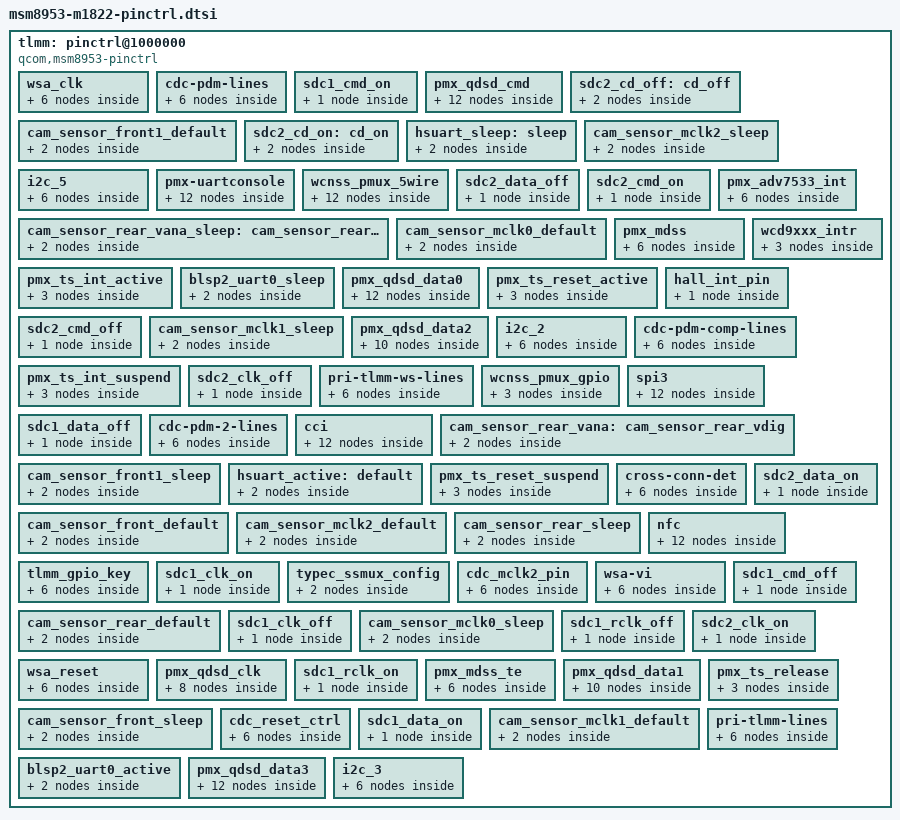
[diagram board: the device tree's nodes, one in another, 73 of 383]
		tlmm: pinctrl@1000000 {
			interrupts-extended = <0x01 0x00 0xd0 0x00>;
			compatible = "qcom,msm8953-pinctrl";
			gpio-controller;
			#interrupt-cells = <0x02>;
			interrupt-parent = <0x10>;
			interrupts = <0x00 0xd0 0x00>;
			phandle = <0xc3>;
			reg = <0x1000000 0x300000>;
			#gpio-cells = <0x02>;
			linux,phandle = <0xc3>;
			interrupt-controller;

			wsa_clk {

				wsa_clk_on: wsa_clk_on {
					phandle = <0x192>;
					linux,phandle = <0x192>;

					mux {
						pins = "gpio25";
						function = "pri_mi2s_mclk_a";
					};

					config {
						pins = "gpio25";
						drive-strength = <0x08>;
						output-high;
					};
				};

				wsa_clk_off: wsa_clk_off {
					phandle = <0x193>;
					linux,phandle = <0x193>;

					mux {
						pins = "gpio25";
						function = "pri_mi2s_mclk_a";
					};

					config {
						output-low;
						pins = "gpio25";
						drive-strength = <0x02>;
						bias-pull-down;
					};
				};
			};

			cdc-pdm-lines {

				cdc_pdm_lines_act: pdm_lines_on {
					phandle = <0x188>;
					linux,phandle = <0x188>;

					mux {
						pins = "gpio69", "gpio73", "gpio74";
						function = "cdc_pdm0";
					};

					config {
						pins = "gpio69", "gpio73", "gpio74";
						drive-strength = <0x08>;
					};
				};

				cdc_pdm_lines_sus: pdm_lines_off {
					phandle = <0x18a>;
					linux,phandle = <0x18a>;

					mux {
						pins = "gpio69", "gpio73", "gpio74";
						function = "cdc_pdm0";
					};

					config {
						pins = "gpio69", "gpio73", "gpio74";
						bias-disable;
						drive-strength = <0x02>;
					};
				};
			};

			sdc1_cmd_on: sdc1_cmd_on {
				phandle = <0x1cb>;
				linux,phandle = <0x1cb>;

				config {
					pins = "sdc1_cmd";
					drive-strength = <0x0a>;
					bias-pull-up;
				};
			};

			pmx_qdsd_cmd {

				qdsd_cmd_trace: cmd_trace {
					phandle = <0x1ed>;
					linux,phandle = <0x1ed>;

					config {
						pins = "qdsd_cmd";
						drive-strength = <0x02>;
						bias-pull-down;
					};
				};

				qdsd_cmd_spmi: cmd_spmi {
					phandle = <0x1f1>;
					linux,phandle = <0x1f1>;

					config {
						pins = "qdsd_cmd";
						drive-strength = <0x0a>;
						bias-pull-down;
					};
				};

				qdsd_cmd_swdtrc: cmd_swdtrc {
					phandle = <0x1ef>;
					linux,phandle = <0x1ef>;

					config {
						pins = "qdsd_cmd";
						drive-strength = <0x02>;
						bias-pull-up;
					};
				};

				qdsd_cmd_sdcard: cmd_sdcard {
					phandle = <0x1ec>;
					linux,phandle = <0x1ec>;

					config {
						pins = "qdsd_cmd";
						drive-strength = <0x08>;
						bias-pull-down;
					};
				};

				qdsd_cmd_swduart: cmd_uart {
					phandle = <0x1ee>;
					linux,phandle = <0x1ee>;

					config {
						pins = "qdsd_cmd";
						drive-strength = <0x02>;
						bias-pull-up;
					};
				};

				qdsd_cmd_jtag: cmd_jtag {
					phandle = <0x1f0>;
					linux,phandle = <0x1f0>;

					config {
						pins = "qdsd_cmd";
						bias-disable;
						drive-strength = <0x08>;
					};
				};
			};

			sdc2_cd_off: cd_off {
				phandle = <0x1d8>;
				linux,phandle = <0x1d8>;

				mux {
					pins = "gpio133";
					function = "gpio";
				};

				config {
					pins = "gpio133";
					bias-disable;
					drive-strength = <0x02>;
				};
			};

			cam_sensor_front1_default: cam_sensor_front1_default {
				phandle = <0x1bf>;
				linux,phandle = <0x1bf>;

				mux {
					pins = "gpio129", "gpio130";
					function = "gpio";
				};

				config {
					pins = "gpio129", "gpio130";
					bias-disable;
					drive-strength = <0x02>;
				};
			};

			sdc2_cd_on: cd_on {
				phandle = <0x1d7>;
				linux,phandle = <0x1d7>;

				mux {
					pins = "gpio133";
					function = "gpio";
				};

				config {
					pins = "gpio133";
					drive-strength = <0x02>;
					bias-pull-up;
				};
			};

			hsuart_sleep: sleep {
				phandle = <0x102>;
				linux,phandle = <0x102>;

				mux {
					pins = "gpio12", "gpio13", "gpio14", "gpio15";
					function = "gpio";
				};

				config {
					pins = "gpio12", "gpio13", "gpio14", "gpio15";
					bias-disable;
					drive-strength = <0x02>;
				};
			};

			cam_sensor_mclk2_sleep: cam_sensor_mclk2_sleep {
				phandle = <0x1be>;
				linux,phandle = <0x1be>;

				mux {
					pins = "gpio28";
					function = "cam_mclk";
				};

				config {
					pins = "gpio28";
					drive-strength = <0x02>;
					bias-pull-down;
				};
			};

			i2c_5 {

				i2c_5_active: i2c_5_active {
					phandle = <0x113>;
					linux,phandle = <0x113>;

					mux {
						pins = "gpio18", "gpio19";
						function = "blsp_i2c5";
					};

					config {
						pins = "gpio18", "gpio19";
						bias-disable;
						drive-strength = <0x02>;
					};
				};

				i2c_5_sleep: i2c_5_sleep {
					phandle = <0x114>;
					linux,phandle = <0x114>;

					mux {
						pins = "gpio18", "gpio19";
						function = "gpio";
					};

					config {
						pins = "gpio18", "gpio19";
						bias-disable;
						drive-strength = <0x02>;
					};
				};
			};

			pmx-uartconsole {

				uart1_console_sleep: uart1_console_sleep {
					phandle = <0x1b2>;
					linux,phandle = <0x1b2>;

					mux {
						pins = "gpio20", "gpio21";
						function = "blsp_uart6";
					};

					config {
						pins = "gpio20", "gpio21";
						drive-strength = <0x02>;
						bias-pull-down;
					};
				};

				uart1_console_active: uart1_console_active {
					phandle = <0x1b1>;
					linux,phandle = <0x1b1>;

					mux {
						pins = "gpio20", "gpio21";
						function = "blsp_uart6";
					};

					config {
						pins = "gpio20", "gpio21";
						bias-disable;
						drive-strength = <0x02>;
					};
				};

				uart_console_sleep: uart_console_sleep {
					phandle = <0x1b0>;
					linux,phandle = <0x1b0>;

					mux {
						pins = "gpio4", "gpio5";
						function = "blsp_uart2";
					};

					config {
						pins = "gpio4", "gpio5";
						drive-strength = <0x02>;
						bias-pull-down;
					};
				};

				uart_console_active: uart_console_active {
					phandle = <0x1af>;
					linux,phandle = <0x1af>;

					mux {
						pins = "gpio4", "gpio5";
						function = "blsp_uart2";
					};

					config {
						pins = "gpio4", "gpio5";
						bias-disable;
						drive-strength = <0x02>;
					};
				};
			};

			wcnss_pmux_5wire {

				wcnss_default: wcnss_default {
					phandle = <0x144>;
					linux,phandle = <0x144>;

					wcss_wlan {
						pins = "gpio79", "gpio80";
						function = "wcss_wlan";
					};

					wcss_wlan1 {
						pins = "gpio77";
						function = "wcss_wlan1";
					};

					config {
						pins = "gpio76", "gpio77", "gpio78", "gpio79", "gpio80";
						drive-strength = <0x06>;
						bias-pull-up;
					};

					wcss_wlan0 {
						pins = "gpio78";
						function = "wcss_wlan0";
					};

					wcss_wlan2 {
						pins = "gpio76";
						function = "wcss_wlan2";
					};
				};

				wcnss_sleep: wcnss_sleep {
					phandle = <0x145>;
					linux,phandle = <0x145>;

					wcss_wlan {
						pins = "gpio79", "gpio80";
						function = "wcss_wlan";
					};

					wcss_wlan1 {
						pins = "gpio77";
						function = "wcss_wlan1";
					};

					config {
						pins = "gpio76", "gpio77", "gpio78", "gpio79", "gpio80";
						drive-strength = <0x02>;
						bias-pull-down;
					};

					wcss_wlan0 {
						pins = "gpio78";
						function = "wcss_wlan0";
					};

					wcss_wlan2 {
						pins = "gpio76";
						function = "wcss_wlan2";
					};
				};
			};

			sdc2_data_off: sdc2_data_off {
				phandle = <0x1d6>;
				linux,phandle = <0x1d6>;

				config {
					pins = "sdc2_data";
					drive-strength = <0x02>;
					bias-pull-up;
				};
			};

			sdc2_cmd_on: sdc2_cmd_on {
				phandle = <0x1d3>;
				linux,phandle = <0x1d3>;

				config {
					pins = "sdc2_cmd";
					drive-strength = <0x0a>;
					bias-pull-up;
				};
			};

			cam_sensor_rear_vana_sleep: cam_sensor_rear_vdig_sleep {
				phandle = <0x1b8>;
				linux,phandle = <0x1b8>;

				mux {
					pins = "gpio134";
					function = "gpio";
				};

				config {
					pins = "gpio134";
					bias-disable;
					drive-strength = <0x02>;
				};
			};

			cam_sensor_mclk0_default: cam_sensor_mclk0_default {
				phandle = <0x1b3>;
				linux,phandle = <0x1b3>;

				mux {
					pins = "gpio26";
					function = "cam_mclk";
				};

				config {
					pins = "gpio26";
					bias-disable;
					drive-strength = <0x02>;
				};
			};

			pmx_adv7533_int: pmx_adv7533_int {
				phandle = <0x1c1>;
				linux,phandle = <0x1c1>;

				adv7533_int_suspend: adv7533_int_suspend {
					phandle = <0x1c3>;
					linux,phandle = <0x1c3>;

					mux {
						pins = "gpio90";
						function = "gpio";
					};

					config {
						pins = "gpio90";
						bias-disable;
						drive-strength = <0x10>;
					};
				};

				adv7533_int_active: adv7533_int_active {
					phandle = <0x1c2>;
					linux,phandle = <0x1c2>;

					mux {
						pins = "gpio90";
						function = "gpio";
					};

					config {
						pins = "gpio90";
						bias-disable;
						drive-strength = <0x10>;
					};
				};
			};

			pmx_mdss: pmx_mdss {
				phandle = <0x1c4>;
				linux,phandle = <0x1c4>;

				mdss_dsi_active: mdss_dsi_active {
					phandle = <0x1c5>;
					linux,phandle = <0x1c5>;

					mux {
						pins = "gpio61";
						function = "gpio";
					};

					config {
						pins = "gpio61";
						bias-disable = <0x00>;
						drive-strength = <0x08>;
						output-high;
					};
				};

				mdss_dsi_suspend: mdss_dsi_suspend {
					phandle = <0x1c6>;
					linux,phandle = <0x1c6>;

					mux {
						pins = "gpio61";
						function = "gpio";
					};

					config {
						pins = "gpio61";
						drive-strength = <0x02>;
						bias-pull-down;
					};
				};
			};

			pmx_ts_int_active {

				ts_int_active: ts_int_active {
					phandle = <0x1e1>;
					linux,phandle = <0x1e1>;

					mux {
						pins = "gpio65";
						function = "gpio";
					};

					config {
						pins = "gpio65";
						drive-strength = <0x08>;
						bias-pull-up;
					};
				};
			};

			blsp2_uart0_sleep: blsp2_uart0_sleep {
				phandle = <0x105>;
				linux,phandle = <0x105>;

				mux {
					pins = "gpio16", "gpio17", "gpio18", "gpio19";
					function = "gpio";
				};

				config {
					pins = "gpio16", "gpio17", "gpio18", "gpio19";
					bias-disable;
					drive-strength = <0x02>;
				};
			};

			wcd9xxx_intr {

				wcd_intr_default: wcd_intr_default {
					phandle = <0x1a2>;
					linux,phandle = <0x1a2>;

					mux {
						pins = "gpio73";
						function = "gpio";
					};

					config {
						pins = "gpio73";
						drive-strength = <0x02>;
						bias-pull-down;
						input-enable;
					};
				};
			};

			pmx_qdsd_data0 {

				qdsd_data0_jtag: data0_jtag {
					phandle = <0x1f6>;
					linux,phandle = <0x1f6>;

					config {
						pins = "qdsd_data0";
						drive-strength = <0x02>;
						bias-pull-up;
					};
				};

				qdsd_data0_swdtrc: data0_swdtrc {
					phandle = <0x1f5>;
					linux,phandle = <0x1f5>;

					config {
						pins = "qdsd_data0";
						drive-strength = <0x02>;
						bias-pull-down;
					};
				};

				qdsd_data0_sdcard: data0_sdcard {
					phandle = <0x1f2>;
					linux,phandle = <0x1f2>;

					config {
						pins = "qdsd_data0";
						drive-strength = <0x08>;
						bias-pull-down;
					};
				};

				qdsd_data0_spmi: data0_spmi {
					phandle = <0x1f7>;
					linux,phandle = <0x1f7>;

					config {
						pins = "qdsd_data0";
						drive-strength = <0x02>;
						bias-pull-down;
					};
				};

				qdsd_data0_trace: data0_trace {
					phandle = <0x1f3>;
					linux,phandle = <0x1f3>;

					config {
						pins = "qdsd_data0";
						drive-strength = <0x08>;
						bias-pull-down;
					};
				};

				qdsd_data0_swduart: data0_uart {
					phandle = <0x1f4>;
					linux,phandle = <0x1f4>;

					config {
						pins = "qdsd_data0";
						drive-strength = <0x02>;
						bias-pull-down;
					};
				};
			};

			pmx_ts_reset_active {

				ts_reset_active: ts_reset_active {
					phandle = <0x1e3>;
					linux,phandle = <0x1e3>;

					mux {
						pins = "gpio64";
						function = "gpio";
					};

					config {
						pins = "gpio64";
						drive-strength = <0x08>;
						bias-pull-up;
					};
				};
			};

			hall_int_pin {
				pins = "gpio13";
				qcom,pin-func = <0x00>;
				label = "hall-irq";
				qcom,num-grp-pins = <0x01>;

				hall_sensor_int_default: hall_sensor_int_default {
					drive-strength = <0x06>;
					phandle = <0x1d9>;
					linux,phandle = <0x1d9>;
					bias-pull-up;
				};
			};

			sdc2_cmd_off: sdc2_cmd_off {
				phandle = <0x1d4>;
				linux,phandle = <0x1d4>;

				config {
					pins = "sdc2_cmd";
					drive-strength = <0x02>;
					bias-pull-up;
				};
			};

			cam_sensor_mclk1_sleep: cam_sensor_mclk1_sleep {
				phandle = <0x1ba>;
				linux,phandle = <0x1ba>;

				mux {
					pins = "gpio27";
					function = "cam_mclk";
				};

				config {
					pins = "gpio27";
					drive-strength = <0x02>;
					bias-pull-down;
				};
			};

			pmx_qdsd_data2 {

				qdsd_data2_trace: data2_trace {
					phandle = <0x1fe>;
					linux,phandle = <0x1fe>;

					config {
						pins = "qdsd_data2";
						drive-strength = <0x08>;
						bias-pull-down;
					};
				};

				qdsd_data2_swduart: data2_uart {
					phandle = <0x1ff>;
					linux,phandle = <0x1ff>;

					config {
						pins = "qdsd_data2";
						drive-strength = <0x02>;
						bias-pull-down;
					};
				};

				qdsd_data2_jtag: data2_jtag {
					phandle = <0x201>;
					linux,phandle = <0x201>;

					config {
						pins = "qdsd_data2";
						drive-strength = <0x08>;
						bias-pull-up;
					};
				};

				qdsd_data2_swdtrc: data2_swdtrc {
					phandle = <0x200>;
					linux,phandle = <0x200>;

					config {
						pins = "qdsd_data2";
						drive-strength = <0x02>;
						bias-pull-down;
					};
				};

				qdsd_data2_sdcard: data2_sdcard {
					phandle = <0x1fd>;
					linux,phandle = <0x1fd>;

					config {
						pins = "qdsd_data2";
						drive-strength = <0x08>;
						bias-pull-down;
					};
				};
			};

			i2c_2 {

				i2c_2_sleep: i2c_2_sleep {
					phandle = <0x10c>;
					linux,phandle = <0x10c>;

					mux {
						pins = "gpio6", "gpio7";
						function = "gpio";
					};

					config {
						pins = "gpio6", "gpio7";
						bias-disable;
						drive-strength = <0x02>;
					};
				};

				i2c_2_active: i2c_2_active {
					phandle = <0x10b>;
					linux,phandle = <0x10b>;

					mux {
						pins = "gpio6", "gpio7";
						function = "blsp_i2c2";
					};

					config {
						pins = "gpio6", "gpio7";
						bias-disable;
						drive-strength = <0x02>;
					};
				};
			};

			cdc-pdm-comp-lines {

				cdc_pdm_comp_lines_act: pdm_comp_lines_on {
					phandle = <0x186>;
					linux,phandle = <0x186>;

					mux {
						pins = "gpio67", "gpio68";
						function = "cdc_pdm0";
					};

					config {
						pins = "gpio67", "gpio68";
						drive-strength = <0x08>;
					};
				};

				cdc_pdm_comp_lines_sus: pdm_comp_lines_off {
					phandle = <0x187>;
					linux,phandle = <0x187>;

					mux {
						pins = "gpio67", "gpio68";
						function = "cdc_pdm0";
					};

					config {
						pins = "gpio67", "gpio68";
						bias-disable;
						drive-strength = <0x02>;
					};
				};
			};

			pmx_ts_int_suspend {

				ts_int_suspend: ts_int_suspend {
					phandle = <0x1e2>;
					linux,phandle = <0x1e2>;

					mux {
						pins = "gpio65";
						function = "gpio";
					};

					config {
						pins = "gpio65";
						drive-strength = <0x02>;
						bias-pull-down;
					};
				};
			};

			sdc2_clk_off: sdc2_clk_off {
				phandle = <0x1d2>;
				linux,phandle = <0x1d2>;

				config {
					pins = "sdc2_clk";
					bias-disable;
					drive-strength = <0x02>;
				};
			};

			pri-tlmm-ws-lines {

				pri_tlmm_ws_act: pri_tlmm_ws_act {
					phandle = <0x18d>;
					linux,phandle = <0x18d>;

					mux {
						pins = "gpio92";
						function = "pri_mi2s_ws";
					};

					config {
						pins = "gpio92";
						drive-strength = <0x08>;
					};
				};

				pri_tlmm_ws_sus: pri_tlmm_ws_sus {
					phandle = <0x18f>;
					linux,phandle = <0x18f>;

					mux {
						pins = "gpio92";
						function = "pri_mi2s_ws";
					};

					config {
						pins = "gpio92";
						drive-strength = <0x02>;
						bias-pull-down;
					};
				};
			};

			wcnss_pmux_gpio: wcnss_pmux_gpio {
				phandle = <0x1de>;
				linux,phandle = <0x1de>;

				wcnss_gpio_default: wcnss_gpio_default {
					phandle = <0x146>;
					linux,phandle = <0x146>;

					mux {
						pins = "gpio76", "gpio77", "gpio78", "gpio79", "gpio80";
						function = "gpio";
					};

					config {
						pins = "gpio76", "gpio77", "gpio78", "gpio79", "gpio80";
						drive-strength = <0x06>;
						bias-pull-up;
					};
				};
			};

			spi3 {

				spi3_cs0_active: cs0_active {
					phandle = <0x108>;
					linux,phandle = <0x108>;

					mux {
						pins = "gpio10";
						function = "blsp_spi3";
					};

					config {
						pins = "gpio10";
						bias-disable = <0x00>;
						drive-strength = <0x02>;
					};
				};

				spi3_default: spi3_default {
					phandle = <0x107>;
					linux,phandle = <0x107>;

					mux {
						pins = "gpio8", "gpio9", "gpio11";
						function = "blsp_spi3";
					};

					config {
						pins = "gpio8", "gpio9", "gpio11";
						bias-disable = <0x00>;
						drive-strength = <0x0c>;
					};
				};

				spi3_cs0_sleep: cs0_sleep {
					phandle = <0x10a>;
					linux,phandle = <0x10a>;

					mux {
						pins = "gpio10";
						function = "gpio";
					};

					config {
						pins = "gpio10";
						bias-disable = <0x00>;
						drive-strength = <0x02>;
					};
				};

				spi3_sleep: spi3_sleep {
					phandle = <0x109>;
					linux,phandle = <0x109>;

					mux {
						pins = "gpio8", "gpio9", "gpio11";
						function = "gpio";
					};

					config {
						pins = "gpio8", "gpio9", "gpio11";
						drive-strength = <0x02>;
						bias-pull-down;
					};
				};
			};

			sdc1_data_off: sdc1_data_off {
				phandle = <0x1ce>;
				linux,phandle = <0x1ce>;

				config {
					pins = "sdc1_data";
					drive-strength = <0x02>;
					bias-pull-up;
				};
			};

			cdc-pdm-2-lines {

				cdc_pdm_lines_2_act: pdm_lines_2_on {
					phandle = <0x189>;
					linux,phandle = <0x189>;

					mux {
						pins = "gpio70", "gpio71", "gpio72";
						function = "cdc_pdm0";
					};

					config {
						pins = "gpio70", "gpio71", "gpio72";
						drive-strength = <0x08>;
					};
				};

				cdc_pdm_lines_2_sus: pdm_lines_2_off {
					phandle = <0x18b>;
					linux,phandle = <0x18b>;

					mux {
						pins = "gpio70", "gpio71", "gpio72";
						function = "cdc_pdm0";
					};

					config {
						pins = "gpio70", "gpio71", "gpio72";
						bias-disable;
						drive-strength = <0x02>;
					};
				};
			};

			cci {

				cci0_active: cci0_active {
					phandle = <0x152>;
					linux,phandle = <0x152>;

					mux {
						pins = "gpio29", "gpio30";
						function = "cci_i2c";
					};

					config {
						pins = "gpio29", "gpio30";
						bias-disable;
						drive-strength = <0x02>;
					};
				};

				cci1_active: cci1_active {
					phandle = <0x153>;
					linux,phandle = <0x153>;

					mux {
						pins = "gpio31", "gpio32";
						function = "cci_i2c";
					};

					config {
						pins = "gpio31", "gpio32";
						bias-disable;
						drive-strength = <0x02>;
					};
				};

				cci1_suspend: cci1_suspend {
					phandle = <0x155>;
					linux,phandle = <0x155>;

					mux {
						pins = "gpio31", "gpio32";
						function = "cci_i2c";
					};

					config {
						pins = "gpio31", "gpio32";
						bias-disable;
						drive-strength = <0x02>;
					};
				};

				cci0_suspend: cci0_suspend {
					phandle = <0x154>;
					linux,phandle = <0x154>;

					mux {
						pins = "gpio29", "gpio30";
						function = "cci_i2c";
					};

					config {
						pins = "gpio29", "gpio30";
						bias-disable;
						drive-strength = <0x02>;
					};
				};
			};

			cam_sensor_rear_vana: cam_sensor_rear_vdig {
				phandle = <0x1b7>;
				linux,phandle = <0x1b7>;

				mux {
					pins = "gpio134";
					function = "gpio";
				};

				config {
					pins = "gpio134";
					bias-disable;
					drive-strength = <0x02>;
				};
			};

			cam_sensor_front1_sleep: cam_sensor_front1_sleep {
				phandle = <0x1c0>;
				linux,phandle = <0x1c0>;

				mux {
					pins = "gpio129", "gpio130";
					function = "gpio";
				};

				config {
					pins = "gpio129", "gpio130";
					bias-disable;
					drive-strength = <0x02>;
				};
			};

			hsuart_active: default {
				phandle = <0x103>;
				linux,phandle = <0x103>;

				mux {
					pins = "gpio12", "gpio13", "gpio14", "gpio15";
					function = "blsp_uart4";
				};

				config {
					pins = "gpio12", "gpio13", "gpio14", "gpio15";
					bias-disable;
					drive-strength = <0x10>;
				};
			};

			pmx_ts_reset_suspend {

				ts_reset_suspend: ts_reset_suspend {
					phandle = <0x1e4>;
					linux,phandle = <0x1e4>;

					mux {
						pins = "gpio64";
						function = "gpio";
					};

					config {
						pins = "gpio64";
						drive-strength = <0x02>;
						bias-pull-down;
					};
				};
			};

			cross-conn-det {

				cross_conn_det_sus: lines_off {
					phandle = <0x185>;
					linux,phandle = <0x185>;

					mux {
						pins = "gpio63";
						function = "gpio";
					};

					config {
						pins = "gpio63";
						drive-strength = <0x02>;
						bias-pull-down;
					};
				};

				cross_conn_det_act: lines_on {
					phandle = <0x184>;
					linux,phandle = <0x184>;

					mux {
						pins = "gpio63";
						function = "gpio";
					};

					config {
						output-low;
						pins = "gpio63";
						drive-strength = <0x08>;
						bias-pull-down;
					};
				};
			};

			cam_sensor_front_default: cam_sensor_front_default {
				phandle = <0x1bb>;
				linux,phandle = <0x1bb>;

				mux {
					pins = "gpio131", "gpio132";
					function = "gpio";
				};

				config {
					pins = "gpio131", "gpio132";
					bias-disable;
					drive-strength = <0x02>;
				};
			};

			sdc2_data_on: sdc2_data_on {
				phandle = <0x1d5>;
				linux,phandle = <0x1d5>;

				config {
					pins = "sdc2_data";
					drive-strength = <0x0a>;
					bias-pull-up;
				};
			};

			cam_sensor_mclk2_default: cam_sensor_mclk2_default {
				phandle = <0x1bd>;
				linux,phandle = <0x1bd>;

				mux {
					pins = "gpio28";
					function = "cam_mclk";
				};

				config {
					pins = "gpio28";
					bias-disable;
					drive-strength = <0x02>;
				};
			};

			cam_sensor_rear_sleep: cam_sensor_rear_sleep {
				phandle = <0x1b6>;
				linux,phandle = <0x1b6>;

				mux {
					pins = "gpio40", "gpio39";
					function = "gpio";
				};

				config {
					pins = "gpio40", "gpio39";
					bias-disable;
					drive-strength = <0x02>;
				};
			};

			nfc {

				nfc_int_suspend: nfc_int_suspend {
					phandle = <0x1db>;
					linux,phandle = <0x1db>;

					mux {
						pins = "gpio17";
						function = "gpio";
					};

					config {
						pins = "gpio17";
						drive-strength = <0x02>;
						bias-pull-up;
					};
				};

				nfc_int_active: nfc_int_active {
					phandle = <0x1da>;
					linux,phandle = <0x1da>;

					mux {
						pins = "gpio17";
						function = "gpio";
					};

					config {
						pins = "gpio17";
						drive-strength = <0x02>;
						bias-pull-up;
					};
				};

				nfc_disable_suspend: nfc_disable_suspend {
					phandle = <0x1dd>;
					linux,phandle = <0x1dd>;

					mux {
						pins = "gpio16", "gpio62", "gpio141";
						function = "gpio";
					};

					config {
						pins = "gpio16", "gpio62", "gpio141";
						bias-disable;
						drive-strength = <0x02>;
					};
				};

				nfc_disable_active: nfc_disable_active {
					phandle = <0x1dc>;
					linux,phandle = <0x1dc>;

					mux {
						pins = "gpio16", "gpio62", "gpio141";
						function = "gpio";
					};

					config {
						pins = "gpio16", "gpio62", "gpio141";
						drive-strength = <0x02>;
						bias-pull-up;
					};
				};
			};

			tlmm_gpio_key {

				gpio_key_active: gpio_key_active {
					phandle = <0x1e6>;
					linux,phandle = <0x1e6>;

					mux {
						pins = "gpio85", "gpio86", "gpio87";
						function = "gpio";
					};

					config {
						pins = "gpio85", "gpio86", "gpio87";
						drive-strength = <0x02>;
						bias-pull-up;
					};
				};

				gpio_key_suspend: gpio_key_suspend {
					phandle = <0x1e7>;
					linux,phandle = <0x1e7>;

					mux {
						pins = "gpio85", "gpio86", "gpio87";
						function = "gpio";
					};

					config {
						pins = "gpio85", "gpio86", "gpio87";
						drive-strength = <0x02>;
						bias-pull-up;
					};
				};
			};

			sdc1_clk_on: sdc1_clk_on {
				phandle = <0x1c9>;
				linux,phandle = <0x1c9>;

				config {
					pins = "sdc1_clk";
					bias-disable;
					drive-strength = <0x10>;
				};
			};

			typec_ssmux_config: typec_ssmux_config {
				phandle = <0x208>;
				linux,phandle = <0x208>;

				mux {
					pins = "gpio139";
					function = "gpio";
				};

				config {
					pins = "gpio139";
					bias-disable;
					drive-strength = <0x02>;
				};
			};

			cdc_mclk2_pin {

				cdc_mclk2_active: cdc_mclk2_active {
					phandle = <0x1e0>;
					linux,phandle = <0x1e0>;

					mux {
						pins = "gpio66";
						function = "pri_mi2s";
					};

					config {
						pins = "gpio66";
						bias-disable;
						drive-strength = <0x08>;
					};
				};

				cdc_mclk2_sleep: cdc_mclk2_sleep {
					phandle = <0x1df>;
					linux,phandle = <0x1df>;

					mux {
						pins = "gpio66";
						function = "pri_mi2s";
					};

					config {
						pins = "gpio66";
						drive-strength = <0x02>;
						bias-pull-down;
					};
				};
			};

			wsa-vi {

				wsa_vi_on: wsa_vi_on {
					phandle = <0x190>;
					linux,phandle = <0x190>;

					mux {
						pins = "gpio94", "gpio95";
						function = "wsa_io";
					};

					config {
						pins = "gpio94", "gpio95";
						bias-disable;
						drive-strength = <0x08>;
					};
				};

				wsa_vi_off: wsa_vi_off {
					phandle = <0x191>;
					linux,phandle = <0x191>;

					mux {
						pins = "gpio94", "gpio95";
						function = "wsa_io";
					};

					config {
						pins = "gpio94", "gpio95";
						drive-strength = <0x02>;
						bias-pull-down;
					};
				};
			};

			sdc1_cmd_off: sdc1_cmd_off {
				phandle = <0x1cc>;
				linux,phandle = <0x1cc>;

				config {
					pins = "sdc1_cmd";
					drive-strength = <0x02>;
					num-grp-pins = <0x01>;
					bias-pull-up;
				};
			};

			cam_sensor_rear_default: cam_sensor_rear_default {
				phandle = <0x1b5>;
				linux,phandle = <0x1b5>;

				mux {
					pins = "gpio40", "gpio39";
					function = "gpio";
				};

				config {
					pins = "gpio40", "gpio39";
					bias-disable;
					drive-strength = <0x02>;
				};
			};

			sdc1_clk_off: sdc1_clk_off {
				phandle = <0x1ca>;
				linux,phandle = <0x1ca>;

				config {
					pins = "sdc1_clk";
					bias-disable;
					drive-strength = <0x02>;
				};
			};

			cam_sensor_mclk0_sleep: cam_sensor_mclk0_sleep {
				phandle = <0x1b4>;
				linux,phandle = <0x1b4>;

				mux {
					pins = "gpio26";
					function = "cam_mclk";
				};

				config {
					pins = "gpio26";
					drive-strength = <0x02>;
					bias-pull-down;
				};
			};

			sdc1_rclk_off: sdc1_rclk_off {
				phandle = <0x1d0>;
				linux,phandle = <0x1d0>;

				config {
					pins = "sdc1_rclk";
					bias-pull-down;
				};
			};

			sdc2_clk_on: sdc2_clk_on {
				phandle = <0x1d1>;
				linux,phandle = <0x1d1>;

				config {
					pins = "sdc2_clk";
					bias-disable;
					drive-strength = <0x10>;
				};
			};

			wsa_reset {

				wsa_reset_off: wsa_reset_off {
					phandle = <0x195>;
					linux,phandle = <0x195>;

					mux {
						pins = "gpio96";
						function = "gpio";
					};

					config {
						output-low;
						pins = "gpio96";
						drive-strength = <0x02>;
					};
				};

				wsa_reset_on: wsa_reset_on {
					phandle = <0x194>;
					linux,phandle = <0x194>;

					mux {
						pins = "gpio96";
						function = "gpio";
					};

					config {
						pins = "gpio96";
						drive-strength = <0x02>;
						output-high;
					};
				};
			};

			pmx_qdsd_clk {

				qdsd_clk_trace: clk_trace {
					phandle = <0x1e9>;
					linux,phandle = <0x1e9>;

					config {
						pins = "qdsd_clk";
						drive-strength = <0x02>;
						bias-pull-down;
					};
				};

				qdsd_clk_spmi: clk_spmi {
					phandle = <0x1eb>;
					linux,phandle = <0x1eb>;

					config {
						pins = "qdsd_clk";
						drive-strength = <0x02>;
						bias-pull-down;
					};
				};

				qdsd_clk_swdtrc: clk_swdtrc {
					phandle = <0x1ea>;
					linux,phandle = <0x1ea>;

					config {
						pins = "qdsd_clk";
						drive-strength = <0x02>;
						bias-pull-down;
					};
				};

				qdsd_clk_sdcard: clk_sdcard {
					phandle = <0x1e8>;
					linux,phandle = <0x1e8>;

					config {
						pins = "qdsd_clk";
						bias-disable;
						drive-strength = <0x10>;
					};
				};
			};

			sdc1_rclk_on: sdc1_rclk_on {
				phandle = <0x1cf>;
				linux,phandle = <0x1cf>;

				config {
					pins = "sdc1_rclk";
					bias-pull-down;
				};
			};

			pmx_mdss_te {

				mdss_te_suspend: mdss_te_suspend {
					phandle = <0x1c8>;
					linux,phandle = <0x1c8>;

					mux {
						pins = "gpio24";
						function = "mdp_vsync";
					};

					config {
						pins = "gpio24";
						drive-strength = <0x02>;
						bias-pull-down;
					};
				};

				mdss_te_active: mdss_te_active {
					phandle = <0x1c7>;
					linux,phandle = <0x1c7>;

					mux {
						pins = "gpio24";
						function = "mdp_vsync";
					};

					config {
						pins = "gpio24";
						drive-strength = <0x02>;
						bias-pull-down;
					};
				};
			};

			pmx_qdsd_data1 {

				qdsd_data1_jtag: data1_jtag {
					phandle = <0x1fc>;
					linux,phandle = <0x1fc>;

					config {
						pins = "qdsd_data1";
						drive-strength = <0x02>;
						bias-pull-down;
					};
				};

				qdsd_data1_swdtrc: data1_swdtrc {
					phandle = <0x1fb>;
					linux,phandle = <0x1fb>;

					config {
						pins = "qdsd_data1";
						drive-strength = <0x02>;
						bias-pull-down;
					};
				};

				qdsd_data1_trace: data1_trace {
					phandle = <0x1f9>;
					linux,phandle = <0x1f9>;

					config {
						pins = "qdsd_data1";
						drive-strength = <0x08>;
						bias-pull-down;
					};
				};

				qdsd_data1_sdcard: data1_sdcard {
					phandle = <0x1f8>;
					linux,phandle = <0x1f8>;

					config {
						pins = "qdsd_data1";
						drive-strength = <0x08>;
						bias-pull-down;
					};
				};

				qdsd_data1_swduart: data1_uart {
					phandle = <0x1fa>;
					linux,phandle = <0x1fa>;

					config {
						pins = "qdsd_data1";
						drive-strength = <0x02>;
						bias-pull-down;
					};
				};
			};

			cam_sensor_front_sleep: cam_sensor_front_sleep {
				phandle = <0x1bc>;
				linux,phandle = <0x1bc>;

				mux {
					pins = "gpio131", "gpio132";
					function = "gpio";
				};

				config {
					pins = "gpio131", "gpio132";
					bias-disable;
					drive-strength = <0x02>;
				};
			};

			pmx_ts_release {

				ts_release: ts_release {
					phandle = <0x1e5>;
					linux,phandle = <0x1e5>;

					mux {
						pins = "gpio65", "gpio64";
						function = "gpio";
					};

					config {
						pins = "gpio65", "gpio64";
						drive-strength = <0x02>;
						bias-pull-down;
					};
				};
			};

			cdc_reset_ctrl {

				cdc_reset_sleep: cdc_reset_sleep {
					phandle = <0x1a5>;
					linux,phandle = <0x1a5>;

					mux {
						pins = "gpio67";
						function = "gpio";
					};

					config {
						output-low;
						pins = "gpio67";
						bias-disable;
						drive-strength = <0x10>;
					};
				};

				cdc_reset_active: cdc_reset_active {
					phandle = <0x1a4>;
					linux,phandle = <0x1a4>;

					mux {
						pins = "gpio67";
						function = "gpio";
					};

					config {
						pins = "gpio67";
						drive-strength = <0x10>;
						bias-pull-down;
						output-high;
					};
				};
			};

			sdc1_data_on: sdc1_data_on {
				phandle = <0x1cd>;
				linux,phandle = <0x1cd>;

				config {
					pins = "sdc1_data";
					drive-strength = <0x0a>;
					bias-pull-up;
				};
			};

			cam_sensor_mclk1_default: cam_sensor_mclk1_default {
				phandle = <0x1b9>;
				linux,phandle = <0x1b9>;

				mux {
					pins = "gpio27";
					function = "cam_mclk";
				};

				config {
					pins = "gpio27";
					bias-disable;
					drive-strength = <0x02>;
				};
			};

			pri-tlmm-lines {

				pri_tlmm_lines_sus: pri_tlmm_lines_sus {
					phandle = <0x18e>;
					linux,phandle = <0x18e>;

					mux {
						pins = "gpio91", "gpio93";
						function = "pri_mi2s";
					};

					config {
						pins = "gpio91", "gpio93";
						drive-strength = <0x02>;
						bias-pull-down;
					};
				};

				pri_tlmm_lines_act: pri_tlmm_lines_act {
					phandle = <0x18c>;
					linux,phandle = <0x18c>;

					mux {
						pins = "gpio91", "gpio93";
						function = "pri_mi2s";
					};

					config {
						pins = "gpio91", "gpio93";
						drive-strength = <0x08>;
					};
				};
			};

			blsp2_uart0_active: blsp2_uart0_active {
				phandle = <0x106>;
				linux,phandle = <0x106>;

				mux {
					pins = "gpio16", "gpio17", "gpio18", "gpio19";
					function = "blsp_uart5";
				};

				config {
					pins = "gpio16", "gpio17", "gpio18", "gpio19";
					bias-disable;
					drive-strength = <0x10>;
				};
			};

			pmx_qdsd_data3 {

				qdsd_data3_spmi: data3_spmi {
					phandle = <0x207>;
					linux,phandle = <0x207>;

					config {
						pins = "qdsd_data3";
						drive-strength = <0x08>;
						bias-pull-down;
					};
				};

				qdsd_data3_swduart: data3_uart {
					phandle = <0x204>;
					linux,phandle = <0x204>;

					config {
						pins = "qdsd_data3";
						drive-strength = <0x02>;
						bias-pull-up;
					};
				};

				qdsd_data3_jtag: data3_jtag {
					phandle = <0x206>;
					linux,phandle = <0x206>;

					config {
						pins = "qdsd_data3";
						drive-strength = <0x02>;
						bias-pull-up;
					};
				};

				qdsd_data3_swdtrc: data3_swdtrc {
					phandle = <0x205>;
					linux,phandle = <0x205>;

					config {
						pins = "qdsd_data3";
						drive-strength = <0x02>;
						bias-pull-up;
					};
				};

				qdsd_data3_trace: data3_trace {
					phandle = <0x203>;
					linux,phandle = <0x203>;

					config {
						pins = "qdsd_data3";
						drive-strength = <0x08>;
						bias-pull-down;
					};
				};

				qdsd_data3_sdcard: data3_sdcard {
					phandle = <0x202>;
					linux,phandle = <0x202>;

					config {
						pins = "qdsd_data3";
						drive-strength = <0x08>;
						bias-pull-down;
					};
				};
			};

			i2c_3 {

				i2c_3_sleep: i2c_3_sleep {
					phandle = <0x10f>;
					linux,phandle = <0x10f>;

					mux {
						pins = "gpio10", "gpio11";
						function = "gpio";
					};

					config {
						pins = "gpio10", "gpio11";
						bias-disable;
						drive-strength = <0x02>;
					};
				};

				i2c_3_active: i2c_3_active {
					phandle = <0x10e>;
					linux,phandle = <0x10e>;

					mux {
						pins = "gpio10", "gpio11";
						function = "blsp_i2c3";
					};

					config {
						pins = "gpio10", "gpio11";
						bias-disable;
						drive-strength = <0x02>;
					};
				};
			};
		};
